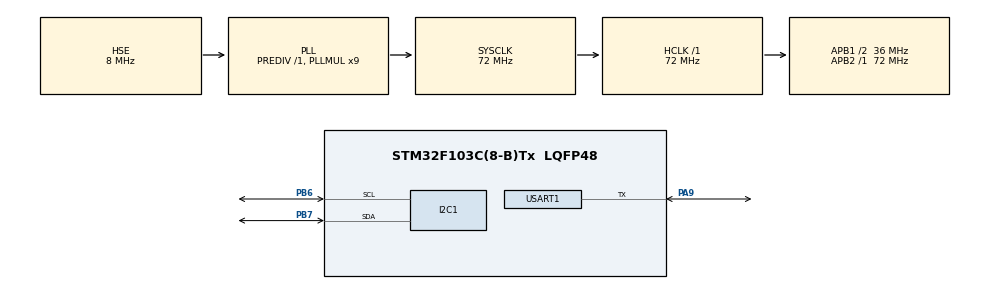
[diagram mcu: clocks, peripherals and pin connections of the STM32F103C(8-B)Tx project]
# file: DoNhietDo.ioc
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I2C1.OwnAddress=0x12
Mcu.Family=STM32F1
Mcu.Name=STM32F103C(8-B)Tx
Mcu.Package=LQFP48
NVIC.I2C1_ER_IRQn=true\:0\:0\:false\:false\:true\:true\:true\:true
NVIC.I2C1_EV_IRQn=true\:0\:0\:false\:false\:true\:true\:true\:true
NVIC.PriorityGroup=NVIC_PRIORITYGROUP_4
NVIC.USART1_IRQn=true\:0\:0\:false\:false\:true\:true\:true\:true
PA13.Mode=Serial_Wire
PA13.Signal=SYS_JTMS-SWDIO
PA14.Mode=Serial_Wire
PA14.Signal=SYS_JTCK-SWCLK
PA9.Mode=Half_duplex(single_wire_mode)
PA9.Signal=USART1_TX
PB6.Mode=I2C
PB6.Signal=I2C1_SCL
PB7.Mode=I2C
PB7.Signal=I2C1_SDA
PD0-OSC_IN.Mode=HSE-External-Oscillator
PD0-OSC_IN.Signal=RCC_OSC_IN
PD1-OSC_OUT.Mode=HSE-External-Oscillator
PD1-OSC_OUT.Signal=RCC_OSC_OUT
ProjectManager.HeapSize=0x200
ProjectManager.StackSize=0x400
ProjectManager.TargetToolchain=STM32CubeIDE
RCC.AHBFreq_Value=72000000
RCC.APB1CLKDivider=RCC_HCLK_DIV2
RCC.APB1Freq_Value=36000000
RCC.APB1TimFreq_Value=72000000
RCC.APB2Freq_Value=72000000
RCC.APB2TimFreq_Value=72000000
RCC.HCLKFreq_Value=72000000
RCC.PLLMUL=RCC_PLL_MUL9
RCC.PLLSourceVirtual=RCC_PLLSOURCE_HSE
RCC.SYSCLKFreq_VALUE=72000000
RCC.SYSCLKSource=RCC_SYSCLKSOURCE_PLLCLK
RCC.USBFreq_Value=72000000
USART1.VirtualMode=VM_ASYNC
board=custom

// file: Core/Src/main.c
/* USER CODE BEGIN Header */
/**
  ******************************************************************************
  * @file           : main.c
  * @brief          : Main program body
  ******************************************************************************
  * @attention
  *
  * Copyright (c) 2024 STMicroelectronics.
  * All rights reserved.
  *
  * This software is licensed under terms that can be found in the LICENSE file
  * in the root directory of this software component.
  * If no LICENSE file comes with this software, it is provided AS-IS.
  *
  ******************************************************************************
  */
/* USER CODE END Header */
#include "main.h"
#include "i2c-lcd.h"
#include <stdio.h>

I2C_HandleTypeDef hi2c1;

UART_HandleTypeDef huart1;

void SystemClock_Config(void);
static void MX_GPIO_Init(void);
static void MX_I2C1_Init(void);
static void MX_USART1_UART_Init(void);

volatile float DS18B20_Temp;
char T[8];

void uart_Init(uint32_t baud){
	huart1.Instance = USART1;
	huart1.Init.BaudRate = baud;
	huart1.Init.WordLength = UART_WORDLENGTH_8B;
	huart1.Init.StopBits = UART_STOPBITS_1;
	huart1.Init.Parity = UART_PARITY_NONE;
	huart1.Init.Mode = UART_MODE_TX_RX;
	huart1.Init.HwFlowCtl = UART_HWCONTROL_NONE;
	huart1.Init.OverSampling = UART_OVERSAMPLING_16;
	if (HAL_HalfDuplex_Init(&huart1) != HAL_OK){
	   Error_Handler();
	}
}
static uint8_t DS18B20_Init(void)
{
	uint8_t ResetByte = 0xF0, PresenceByte;
	uart_Init (9600); // cho 480 us
	// Send reset pulse (0xF0)
	HAL_UART_Transmit(&huart1, &ResetByte, 1, 10);
	// Wait for the presence pulse
	HAL_UART_Receive(&huart1, &PresenceByte, 1, 10);
	uart_Init(115200);
	// Check presence pulse
	if (PresenceByte != ResetByte){
		return 1; // Presence pulse detected
	}
	else{
		return 0; // No presence pulse detected
	}
}

static uint8_t DS18B20_ReadBit(void)
{
    uint8_t ReadBitCMD = 0xFF;
    uint8_t RxBit;

    // Send Read Bit CMD
    HAL_UART_Transmit(&huart1, &ReadBitCMD, 1, 1);
    // Receive The Bit
    HAL_UART_Receive(&huart1, &RxBit, 1, 1);

    return (RxBit & 0x01);
}

static uint8_t DS18B20_ReadByte(void)
{
	uint8_t RxByte = 0;
	for (uint8_t i = 0; i < 8; i++)
	{
		RxByte >>= 1;
		if (DS18B20_ReadBit())
		{
			RxByte |= 0x80;
		}
	}
	return RxByte;
}

static void DS18B20_WriteByte(uint8_t data)
{
	uint8_t TxBuffer[8];
    for (int i=0; i<8; i++)
    {
	  if ((data & (1<<i)) != 0){
		  TxBuffer[i] = 0xFF;
	  }
	  else{
		  TxBuffer[i] = 0;
	  }
    }
    HAL_UART_Transmit(&huart1, TxBuffer, 8, 10);
}

void DS18B20_SampleTemp(void)
{
	DS18B20_Init();
	DS18B20_WriteByte(0xCC);  // Skip ROM   (ROM-CMD)
	DS18B20_WriteByte(0x44);  // Convert T  (F-CMD)
}

float DS18B20_ReadTemp(void)
{
	uint8_t Temp_LSB, Temp_MSB;
	uint16_t Temp;
	float Temperature;

	DS18B20_Init();
	DS18B20_WriteByte(0xCC);  // Skip ROM         (ROM-CMD)
	DS18B20_WriteByte(0xBE);  // Read Scratchpad  (F-CMD)
	Temp_LSB = DS18B20_ReadByte();
	Temp_MSB = DS18B20_ReadByte();
	Temp = ((Temp_MSB<<8))|Temp_LSB;
	Temperature = (float)Temp/16.0;

	return Temperature;
}

//void GetTemp(char* str, float Temp){
//	if (Temp < 0) {
//		*str = '-';
//		str++;
//		Temp = -Temp;
//	}else{
//		*str = '+';
//		str++;
//	}
//	int temp = Temp;
//	int index = 0;
//	while (temp){
//		temp = temp /10;
//		index ++;
//	}
//	temp = Temp;
//	Temp = Temp - temp;
//	int a;
//	for(int i = 0; i < index; i++){
//		a = temp % 10;
//		temp = temp/10;
//		*(str + index - i) = a + 48;
//	}
//	str = str + index;
//	temp = Temp * 1000;
//	for(int i = 0; i < 3; i++){
//		a = temp % 10;
//		temp = temp/10;
//		*(str + 3 - i) = a + 48;
//	}
//}

int main(void)
{

  /* MCU Configuration--------------------------------------------------------*/

  /* Reset of all peripherals, Initializes the Flash interface and the Systick. */
  HAL_Init();

  /* Configure the system clock */
  SystemClock_Config();

  /* Initialize all configured peripherals */
  MX_GPIO_Init();
  MX_I2C1_Init();
  MX_USART1_UART_Init();
  /* Infinite loop */
  /* USER CODE BEGIN WHILE */
  lcd_init ();

  lcd_clear();
  HAL_Delay(100);
  lcd_put_cur(0, 0);
  lcd_send_string ("Nhiet do :");
  while (1)
  {
    /* USER CODE END WHILE */
	  DS18B20_SampleTemp();
	  HAL_Delay(750);
	  DS18B20_Temp = DS18B20_ReadTemp();
	  sprintf(T, "%.3f", DS18B20_Temp);
	  lcd_put_cur(1, 0);
	  lcd_send_string("          ");
	  lcd_put_cur(1, 0);
	  lcd_send_string(T);
	  HAL_Delay(1000);
  }
}

void SystemClock_Config(void)
{
  RCC_OscInitTypeDef RCC_OscInitStruct = {0};
  RCC_ClkInitTypeDef RCC_ClkInitStruct = {0};

  /** Initializes the RCC Oscillators according to the specified parameters
  * in the RCC_OscInitTypeDef structure.
  */
  RCC_OscInitStruct.OscillatorType = RCC_OSCILLATORTYPE_HSE;
  RCC_OscInitStruct.HSEState = RCC_HSE_ON;
  RCC_OscInitStruct.HSEPredivValue = RCC_HSE_PREDIV_DIV1;
  RCC_OscInitStruct.HSIState = RCC_HSI_ON;
  RCC_OscInitStruct.PLL.PLLState = RCC_PLL_ON;
  RCC_OscInitStruct.PLL.PLLSource = RCC_PLLSOURCE_HSE;
  RCC_OscInitStruct.PLL.PLLMUL = RCC_PLL_MUL9;
  if (HAL_RCC_OscConfig(&RCC_OscInitStruct) != HAL_OK)
  {
    Error_Handler();
  }

  /** Initializes the CPU, AHB and APB buses clocks
  */
  RCC_ClkInitStruct.ClockType = RCC_CLOCKTYPE_HCLK|RCC_CLOCKTYPE_SYSCLK
                              |RCC_CLOCKTYPE_PCLK1|RCC_CLOCKTYPE_PCLK2;
  RCC_ClkInitStruct.SYSCLKSource = RCC_SYSCLKSOURCE_PLLCLK;
  RCC_ClkInitStruct.AHBCLKDivider = RCC_SYSCLK_DIV1;
  RCC_ClkInitStruct.APB1CLKDivider = RCC_HCLK_DIV2;
  RCC_ClkInitStruct.APB2CLKDivider = RCC_HCLK_DIV1;

  if (HAL_RCC_ClockConfig(&RCC_ClkInitStruct, FLASH_LATENCY_2) != HAL_OK)
  {
    Error_Handler();
  }
}

static void MX_I2C1_Init(void)
{

  hi2c1.Instance = I2C1;
  hi2c1.Init.ClockSpeed = 100000;
  hi2c1.Init.DutyCycle = I2C_DUTYCYCLE_2;
  hi2c1.Init.OwnAddress1 = 36;
  hi2c1.Init.AddressingMode = I2C_ADDRESSINGMODE_7BIT;
  hi2c1.Init.DualAddressMode = I2C_DUALADDRESS_DISABLE;
  hi2c1.Init.OwnAddress2 = 0;
  hi2c1.Init.GeneralCallMode = I2C_GENERALCALL_DISABLE;
  hi2c1.Init.NoStretchMode = I2C_NOSTRETCH_DISABLE;
  if (HAL_I2C_Init(&hi2c1) != HAL_OK)
  {
    Error_Handler();
  }

}

static void MX_USART1_UART_Init(void)
{

  huart1.Instance = USART1;
  huart1.Init.BaudRate = 115200;
  huart1.Init.WordLength = UART_WORDLENGTH_8B;
  huart1.Init.StopBits = UART_STOPBITS_1;
  huart1.Init.Parity = UART_PARITY_NONE;
  huart1.Init.Mode = UART_MODE_TX_RX;
  huart1.Init.HwFlowCtl = UART_HWCONTROL_NONE;
  huart1.Init.OverSampling = UART_OVERSAMPLING_16;
  if (HAL_HalfDuplex_Init(&huart1) != HAL_OK)
  {
    Error_Handler();
  }

}

static void MX_GPIO_Init(void)
{

  /* GPIO Ports Clock Enable */
  __HAL_RCC_GPIOD_CLK_ENABLE();
  __HAL_RCC_GPIOA_CLK_ENABLE();
  __HAL_RCC_GPIOB_CLK_ENABLE();

}

void Error_Handler(void)
{
  __disable_irq();
  while (1)
  {
  }
}
